# mb9bf566k register map
Vendor: Cypress; Series: mb9bf560l; File version: 1.2
CPU: CM4 r0p1, little endian, MPU, FPU, 4 interrupt priority bits
Registers are 8-bit, read-write, reset 0x0 unless marked. A register's access mark holds for its fields unless they carry their own. Offsets are from the block's base; [hi:lo] are bit positions; {n}, {i} and the like mark numbered series.

## RTC — REAL-TIME CLOCK
Base 0x4003B000
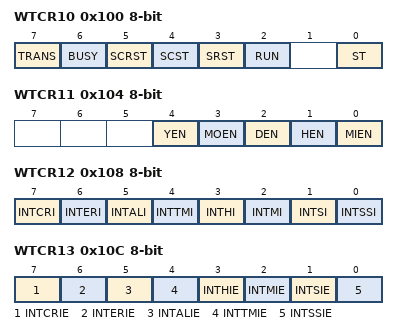
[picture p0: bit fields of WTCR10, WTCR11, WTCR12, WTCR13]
0x100 WTCR10 — Control Register 10
  [7] TRANS ro — Transfer flag bit
  [6] BUSY ro — Busy bit
  [5] SCRST — Sub second generation/1-second generation counter reset bit
  [4] SCST — 1-second clock output stop bit
  [3] SRST — RTC reset bit
  [2] RUN ro — RTC count block operation bit
  [0] ST — Start bit
0x104 WTCR11 — Control Register 11
  [4] YEN — Alarm year register enable bit
  [3] MOEN — Alarm month register enable bit
  [2] DEN — Alarm day register enable bit
  [1] HEN — Alarm hour register enable bit
  [0] MIEN — Alarm minute register enable bit
0x108 WTCR12 — Control Register 12
  [7] INTCRI — Year/month/date/hour/minute/second/day of the week counter value read completion interrupt flag bit
  [6] INTERI — Time rewrite error interrupt flag bit
  [5] INTALI — Alarm coincidence flag bit
  [4] INTTMI — Timer underflow detection flag bit
  [3] INTHI — Every hour flag bit
  [2] INTMI — Every minute flag bit
  [1] INTSI — Every second flag bit
  [0] INTSSI — Every 0.5-second flag bit
0x10C WTCR13 — Control Register 13
  [7] INTCRIE — Year/month/date/hour/minute/second/day of the week counter value read completion interrupt enable bit
  [6] INTERIE — Time rewrite error interrupt enable bit
  [5] INTALIE — Alarm coincidence interrupt enable bit
  [4] INTTMIE — Timer underflow interrupt enable bit
  [3] INTHIE — Every hour interrupt enable bit
  [2] INTMIE — Every minute interrupt enable bit
  [1] INTSIE — Every second interrupt enable bit
  [0] INTSSIE — Every 0.5-second interrupt enable bit
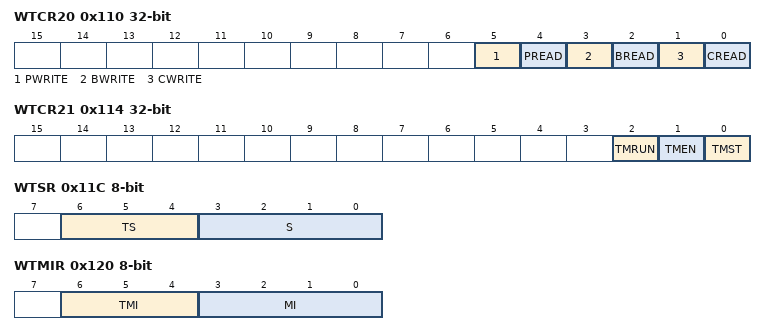
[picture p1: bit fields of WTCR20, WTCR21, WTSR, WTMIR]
0x110 WTCR20 32-bit — Control Register 20
  [5] PWRITE — VBAT PORT save control bit
  [4] PREAD — VBAT PORT recall control bit
  [3] BWRITE — Back up register save control bit
  [2] BREAD — Back up register recall control bit
  [1] CWRITE — RTC setting save control bit
  [0] CREAD — RTC setting recall control bit
0x114 WTCR21 32-bit — Control Register 21
  [2] TMRUN ro — Timer counter operation bit
  [1] TMEN — Timer counter control bit
  [0] TMST — Timer counter start bit
0x11C WTSR — Second Register
  [6:4] TS — 2nd digit of the second information
  [3:0] S — 1st digit of the second information
0x120 WTMIR — Minute Register
  [6:4] TMI — 2nd digit of the minute information
  [3:0] MI — 1st digit of the minute information
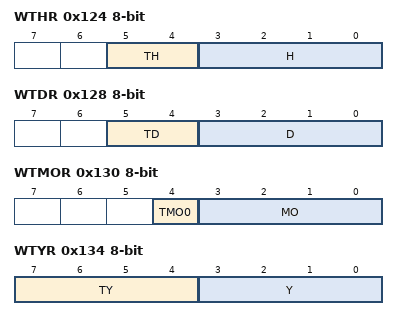
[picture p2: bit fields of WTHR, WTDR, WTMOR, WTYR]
0x124 WTHR — Hour register
  [5:4] TH — 2nd digit of the hour information
  [3:0] H — 1st digit of the hour information
0x128 WTDR — Day Register
  [5:4] TD — 2nd digit of the day information
  [3:0] D — 1st digit of the day information
0x12C WTDW — Day of the Week Register
  [2:0] DW — Day of the week information
0x130 WTMOR — Month Register
  [4] TMO0 — 2nd digit of the month information
  [3:0] MO — 1st digit of the month information
0x134 WTYR — Year Register
  [7:4] TY — 2nd digit of the year information
  [3:0] Y — 1st digit of the year information
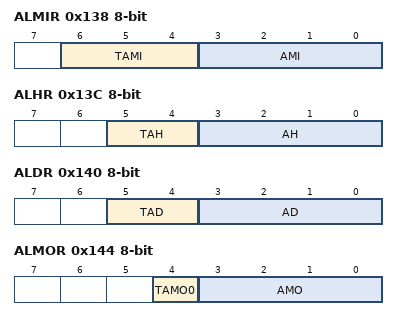
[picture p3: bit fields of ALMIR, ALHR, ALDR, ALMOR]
0x138 ALMIR — Alarm Minute Register
  [6:4] TAMI — 2nd digit of the alarm-set minute information
  [3:0] AMI — 1st digit of the alarm-set minute information
0x13C ALHR — Alarm Hour Register
  [5:4] TAH — 2nd digit of the alarm-set hour information
  [3:0] AH — 1st digit of the alarm-set hour information
0x140 ALDR — Alarm Date Register
  [5:4] TAD — 2nd digit of the alarm-set date information
  [3:0] AD — 1st digit of the alarm-set date information
0x144 ALMOR — Alarm Month Register
  [4] TAMO0 — 2nd digit of the alarm-set month information
  [3:0] AMO — 1st digit of the alarm-set month information
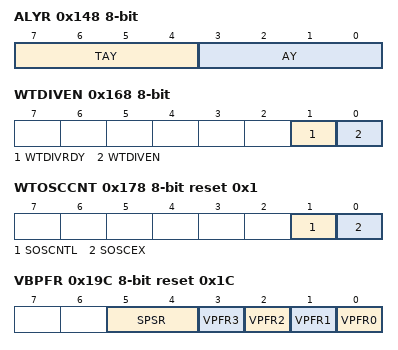
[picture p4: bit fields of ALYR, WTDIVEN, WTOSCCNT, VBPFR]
0x148 ALYR — Alarm Years Register
  [7:4] TAY — 2nd digit of the alarm-set year information
  [3:0] AY — 1st digit of the alarm-set year information
0x14C WTTR0 — Timer Setting Register 0
  [7:0] TM7_0 — Timer Setting Register
0x150 WTTR1 — Timer Setting Register 1
  [7:0] TM15_8 — Timer Setting Register
0x154 WTTR2 — Timer Setting Register 2
  [1:0] TM17_16 — Timer Setting Register
0x158 WTCAL0 — Frequency Correction Value Setting Register 0
  [7:0] WTCAL0 — Frequency correction value setting bits 0
0x15C WTCAL1 — Frequency Correction Value Setting Register 1
  [1:0] WTCAL1 — Frequency correction value setting bits 1
0x160 WTCALEN — Frequency Correction Enable Register
  [0] WTCALEN — Frequency correction enable bit
0x164 WTDIV — Division Ratio Setting Register
  [3:0] WTDIV — Division ration setting bits
0x168 WTDIVEN — Divider Output Enable Register
  [1] WTDIVRDY ro — Divider state bit
  [0] WTDIVEN — Divider enable bit
0x16C WTCALPRD reset 0x13 — Frequency Correction Period Setting Register
  [5:0] WTCALPRD — Frequency correction value setting bits
0x170 WTCOSEL — RTCCO Output Selection Register
  [0] WTCOSEL — RTCCO output selection bit
0x174 VB_CLKDIV reset 0x7
  [7:0] DIV — Transfer clock set bits
0x178 WTOSCCNT reset 0x1
  [1] SOSCNTL — Cooperative operation control bit
  [0] SOSCEX — Oscillation enable bit
0x17C CCS reset 0x8
  [7:0] CCS — Oscillation sustain current set bits
0x180 CCB reset 0x10
  [7:0] CCB — Oscillation boost current set bits
0x188 BOOST reset 0x3
  [1:0] BOOST — Oscillation boost time set bits
0x18C EWKUP
  [0] WUP0 — Wakeup request bit
0x190 VDET reset 0x80
  [7] PON — Power-on bit
0x198 HIBRST
  [0] HIBRST — Hibernation start bit
0x19C VBPFR reset 0x1C — Port Function Set Register
  [5:4] SPSR — Oscillation pin function set bits
  [3] VPFR3 — Port function of P46/X0A pin set bit
  [2] VPFR2 — Port function of P47/X1A pin set bit
  [1] VPFR1 — Port function of P49/VWAKEUP pin set bit
  [0] VPFR0 — Port function of P48/VREGCTL pin set bit
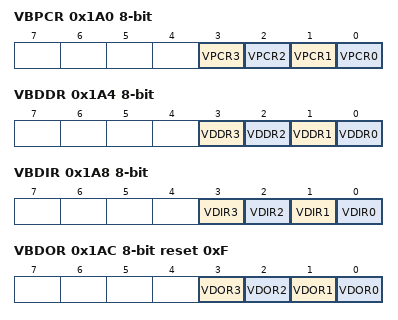
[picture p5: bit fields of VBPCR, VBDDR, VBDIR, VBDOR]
0x1A0 VBPCR — Pull-up Set Register
  [3] VPCR3 — P46/X0A pin pull-up set bit
  [2] VPCR2 — P47/X1A pin pull-up set bit
  [1] VPCR1 — P49/VWAKEUP pin pull-up set bit
  [0] VPCR0 — P48/VREGCTL pin pull-up set bit
0x1A4 VBDDR — Port I/O Direction Set Register
  [3] VDDR3 — Port direction of P46/X0A pin set bit
  [2] VDDR2 — Port direction of P47/X1A pin set bit
  [1] VDDR1 — Port direction of P49/VWAKEUP pin set bit
  [0] VDDR0 — Port direction of P48/VREGCTL pin set bit
0x1A8 VBDIR — Port Input Data Register
  [3] VDIR3 — Port input data of P46/X0A pin bit
  [2] VDIR2 — Port input data of P47/X1A pin bit
  [1] VDIR1 — Port input data of P49/VWAKEUP pin bit
  [0] VDIR0 — Port input data of P48/VREGCTL pin bit
0x1AC VBDOR reset 0xF — Port Output Data Register
  [3] VDOR3 — Port output data of P46/X0A pin bit
  [2] VDOR2 — Port output data of P47/X1A pin bit
  [1] VDOR1 — Port output data of P49/VWAKEUP pin bit
  [0] VDOR0 — Port output data of P48/VREGCTL pin bit
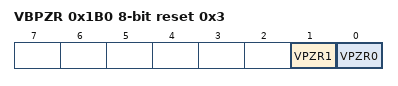
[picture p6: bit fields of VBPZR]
0x1B0 VBPZR reset 0x3 — Port Pseudo-Open Drain Set Register
  [1] VPZR1 — P49/VWAKEUP pin pseudo-open drain set bit
  [0] VPZR0 — P48/VREGCTL pin pseudo-open drain set bit
{0x200+i} BREG{i:02} (i=0..9) — Backup Register
{0x20A+0x10*i} BREG{i}A (i=0..7) — Backup Register
{0x20B+0x10*i} BREG{i}B (i=0..7) — Backup Register
{0x20C+0x10*i} BREG{i}C (i=0..7) — Backup Register
{0x20D+0x10*i} BREG{i}D (i=0..7) — Backup Register
{0x20E+0x10*i} BREG{i}E (i=0..7) — Backup Register
{0x20F+0x10*i} BREG{i}F (i=0..7) — Backup Register
{0x206+i} BREG{i} (i=10..19) — Backup Register
{0x20C+i} BREG{i} (i=20..29) — Backup Register
{0x212+i} BREG{i} (i=30..39) — Backup Register
{0x218+i} BREG{i} (i=40..49) — Backup Register
{0x21E+i} BREG{i} (i=50..59) — Backup Register
{0x224+i} BREG{i} (i=60..69) — Backup Register
{0x22A+i} BREG{i} (i=70..79) — Backup Register
